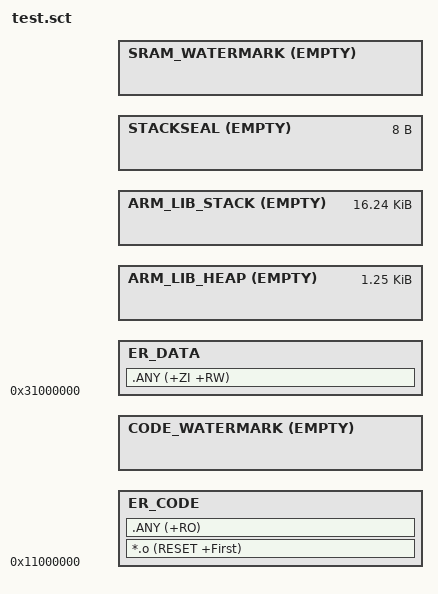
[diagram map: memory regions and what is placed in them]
#! armclang --target=arm-arm-none-eabi -march=armv8.1-m.main -E -xc

/* Secure Code */
#define S_ROM_ALIAS               (0x11000000) /* SRAM_BASE_S */
#define TOTAL_S_ROM_SIZE          (0x00080000) /* 128 kB */

/* Secure Data */
#define S_RAM_ALIAS               (0x31000000) /* ISRAM0_BASE_S */
#define TOTAL_S_RAM_SIZE          (0x00220000) /* 256 kB */

/* Non-Secure Code */
#define NS_ROM_ALIAS              (0x01000000 + 0x00020000) /* SRAM_BASE_NS */
#define TOTAL_NS_ROM_SIZE         (0x00020000) /* 128 kB */

/* Non-Secure Data */
#define NS_RAM_ALIAS              (0x21000000 + 0x00040000) /* ISRAM0_BASE_NS */
#define TOTAL_NS_RAM_SIZE         (0x00040000) /* 256 kB */

/* Heap and Stack sizes for secure and nonsecure applications */
#define HEAP_SIZE                 (0x00000500) /* 1 KiB */
#define STACK_SIZE                (0x00004100) /* 1 KiB */


/* Secure regions */
#define S_CODE_START     ( S_ROM_ALIAS )
#define S_CODE_SIZE      ( TOTAL_S_ROM_SIZE )
#define S_CODE_LIMIT     ( S_CODE_START + S_CODE_SIZE )

#define S_DATA_START     ( S_RAM_ALIAS )
#define S_DATA_SIZE      ( TOTAL_S_RAM_SIZE )
#define S_DATA_LIMIT     ( S_DATA_START + S_DATA_SIZE )

/* Non-Secure regions */
#define NS_CODE_START    ( NS_ROM_ALIAS )
#define NS_CODE_SIZE     ( TOTAL_NS_ROM_SIZE )
#define NS_CODE_LIMIT    ( NS_CODE_START + NS_CODE_SIZE )

#define NS_DATA_START    ( NS_RAM_ALIAS )
#define NS_DATA_SIZE     ( TOTAL_NS_RAM_SIZE )
#define NS_DATA_LIMIT    ( NS_DATA_START + NS_DATA_SIZE )

LR_CODE S_CODE_START {
    ER_CODE S_CODE_START {
        *.o (RESET +First)
        .ANY (+RO)
    }

    /* This empty, zero long execution region is here to mark the limit address
     * of the last execution region that is allocated in SRAM.
     */
    CODE_WATERMARK +0 EMPTY 0x0 {
    }
    /* Make sure that the sections allocated in the SRAM does not exceed the
     * size of the SRAM available.
     */
    ScatterAssert(ImageLimit(CODE_WATERMARK) <= S_CODE_START + S_CODE_SIZE)

    ER_DATA S_DATA_START {
        .ANY (+ZI +RW)
    }

    #if HEAP_SIZE > 0
    ARM_LIB_HEAP +0 ALIGN 8 EMPTY  HEAP_SIZE  {   ; Reserve empty region for heap
    }
    #endif

    ARM_LIB_STACK +0 ALIGN 32 EMPTY STACK_SIZE - 0x8 {   ; Reserve empty region for stack
    }

    STACKSEAL +0 EMPTY 0x8 {
    }

    /* This empty, zero long execution region is here to mark the limit address
     * of the last execution region that is allocated in SRAM.
     */
    SRAM_WATERMARK +0 EMPTY 0x0 {
    }
    /* Make sure that the sections allocated in the SRAM does not exceed the
     * size of the SRAM available.
     */
    ScatterAssert(ImageLimit(SRAM_WATERMARK) <= S_DATA_START + S_DATA_SIZE)
}
